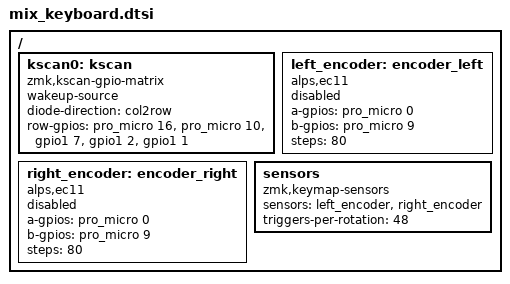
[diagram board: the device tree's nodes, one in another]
#include "mixlayout.dtsi"

/ {
    kscan0: kscan {
        compatible = "zmk,kscan-gpio-matrix";
        wakeup-source;

        diode-direction = "col2row";
        row-gpios
            = <&pro_micro 16 (GPIO_ACTIVE_HIGH | GPIO_PULL_DOWN)>
            , <&pro_micro 10 (GPIO_ACTIVE_HIGH | GPIO_PULL_DOWN)>
            , <&gpio1 7 (GPIO_ACTIVE_HIGH | GPIO_PULL_DOWN)>
            , <&gpio1 2 (GPIO_ACTIVE_HIGH | GPIO_PULL_DOWN)>
            , <&gpio1 1 (GPIO_ACTIVE_HIGH | GPIO_PULL_DOWN)>
            ;

    };

    left_encoder: encoder_left {
        compatible = "alps,ec11";
        a-gpios = <&pro_micro 0 (GPIO_ACTIVE_HIGH | GPIO_PULL_UP)>;
        b-gpios = <&pro_micro 9 (GPIO_ACTIVE_HIGH | GPIO_PULL_UP)>;
        steps = <80>;
        status = "disabled";
    };

    right_encoder: encoder_right {
        compatible = "alps,ec11";
        a-gpios = <&pro_micro 0 (GPIO_ACTIVE_HIGH | GPIO_PULL_UP)>;
        b-gpios = <&pro_micro 9 (GPIO_ACTIVE_HIGH | GPIO_PULL_UP)>;
        steps = <80>;
        status = "disabled";
    };

    sensors: sensors {
        compatible = "zmk,keymap-sensors";
        sensors = <&left_encoder &right_encoder>;
        triggers-per-rotation = <48>;
    };
};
